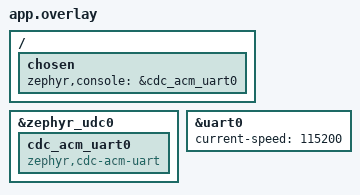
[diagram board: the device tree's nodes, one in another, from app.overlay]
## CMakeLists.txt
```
cmake_minimum_required(VERSION 3.20)
find_package(Zephyr REQUIRED HINTS $ENV{ZEPHYR_BASE})
project(console_test_app)

target_sources(app PRIVATE src/main.c)
```

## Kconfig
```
# Copyright (c) 2023 Nordic Semiconductor ASA
# SPDX-License-Identifier: Apache-2.0

# Source common USB sample options used to initialize new experimental USB
# device stack. The scope of these options is limited to USB samples in project
# tree, you cannot use them in your own application.
# source "samples/subsys/usb/common/Kconfig.sample_usbd"

source "Kconfig.zephyr"

menuconfig CONSOLE_TEST_APP
    bool "Console Test Application"
    default y
    depends on DT_HAS_CUSTOM_SENSOR_NODE_ENABLED
    help
      Enable the console test application.

if CONSOLE_TEST_APP

config CONSOLE_TEST_APP_INIT_PRIORITY
    int "Console test app init priority"
    default 90
    help
      Application initialization priority.

endif # CONSOLE_TEST_APP
```

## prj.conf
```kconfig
# USB Configuration
CONFIG_USB_DEVICE_STACK=y
CONFIG_USB_CDC_ACM=y
CONFIG_USB_DEVICE_PRODUCT="Raspberry Pi Pico"
CONFIG_USB_DEVICE_PID=0x0004
CONFIG_USB_DEVICE_VID=0x2E8A
CONFIG_USB_DEVICE_MANUFACTURER="Raspberry Pi"
CONFIG_USB_DEVICE_INITIALIZE_AT_BOOT=y

# Console and logging over USB and UART
CONFIG_CONSOLE=y
CONFIG_UART_CONSOLE=y
# CONFIG_UART_CONSOLE=n

# UART for sensor data
CONFIG_SERIAL=y
CONFIG_UART_INTERRUPT_DRIVEN=y

# Logging
CONFIG_LOG=y
CONFIG_LOG_DEFAULT_LEVEL=2
CONFIG_LOG_PRINTK=y
```

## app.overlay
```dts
/* Minimal overlay for UART0 to USB CDC ACM bridge on Raspberry Pi Pico */

/ {
	chosen {
		zephyr,console = &cdc_acm_uart0;
	};
};

&zephyr_udc0 {
	cdc_acm_uart0: cdc_acm_uart0 {
		compatible = "zephyr,cdc-acm-uart";
		status = "okay";
	};
};

&uart0 {
	status = "okay";
	current-speed = <115200>;
};
```

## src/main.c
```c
#include <zephyr/kernel.h>
#include <zephyr/device.h>
#include <zephyr/drivers/sensor.h>
#include <zephyr/logging/log.h>
#include <zephyr/usb/usb_device.h>

LOG_MODULE_REGISTER(main, LOG_LEVEL_INF);

void main(void)
{
    usb_enable(NULL);
    printk("UART base node ready!\n");
    LOG_INF("UART base node ready!");

    const struct device *sensor_dev = DEVICE_DT_GET_ANY(mycompany_sensor_node);
    if (!device_is_ready(sensor_dev)) {
        LOG_ERR("Sensor node device not ready!");
        return;
    }

    while (1) {
        struct sensor_value lux;
        int ret = sensor_sample_fetch_chan(sensor_dev, SENSOR_CHAN_LIGHT);
        if (ret == 0) {
            ret = sensor_channel_get(sensor_dev, SENSOR_CHAN_LIGHT, &lux);
            if (ret == 0) {
                printk("[UART] Light: %d.%06d lux\n", lux.val1, lux.val2);
            } else {
                printk("[UART] Failed to get sensor value: %d\n", ret);
            }
        } else {
            printk("[UART] Failed to fetch sensor sample: %d\n", ret);
        }
        k_sleep(K_MSEC(1000));
    }
}
```
